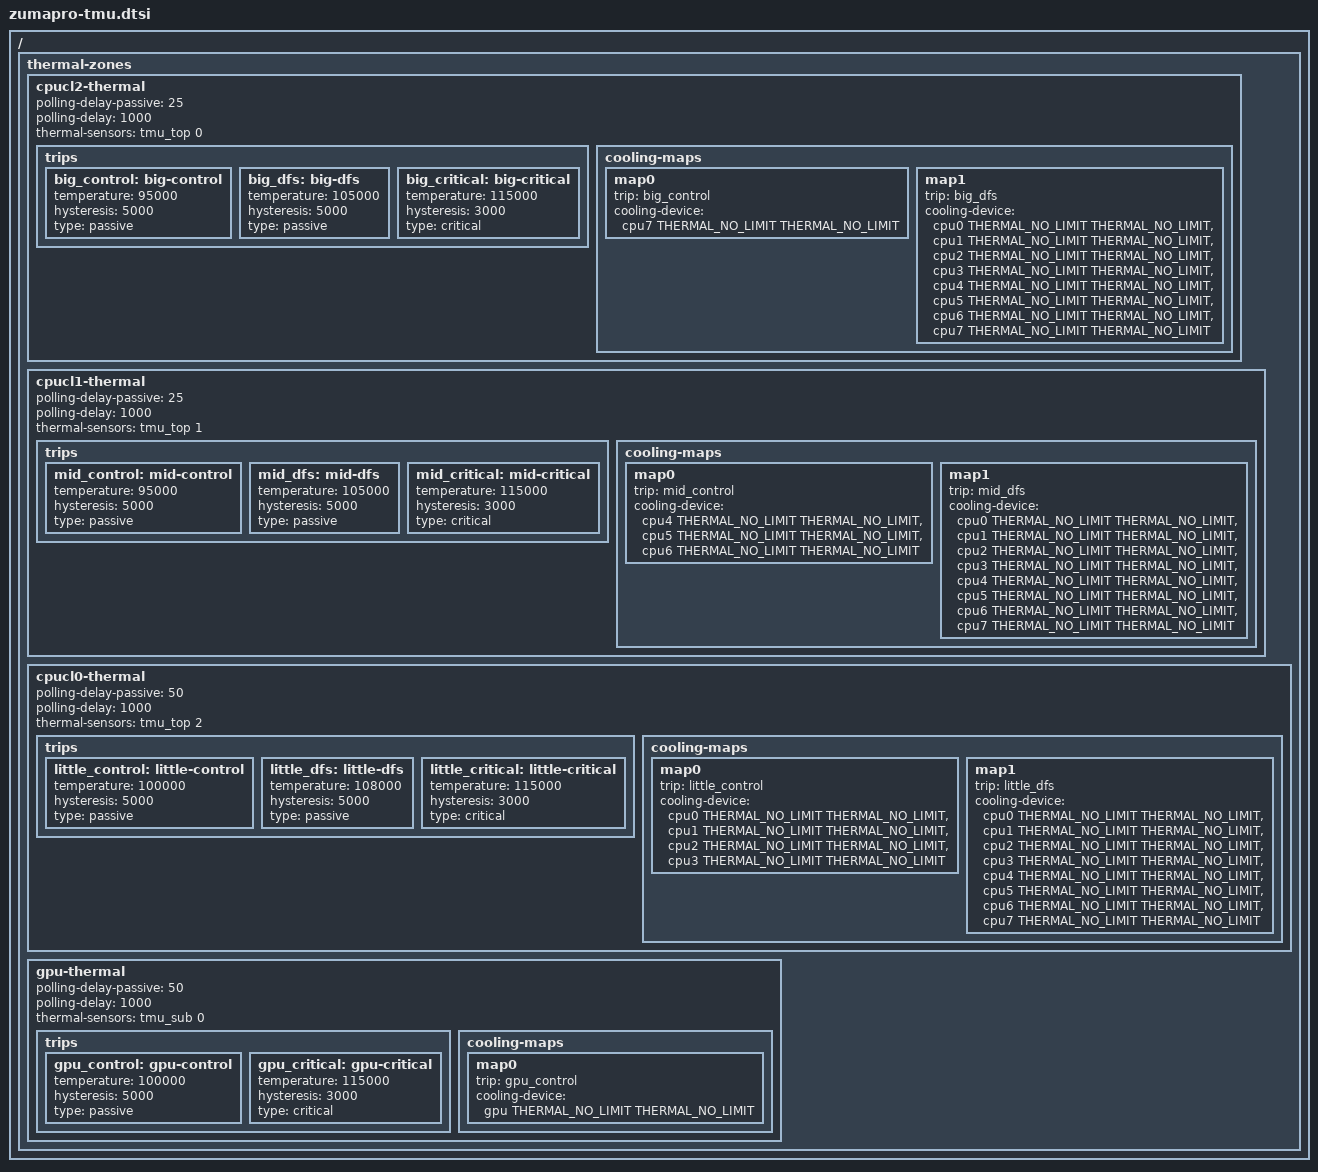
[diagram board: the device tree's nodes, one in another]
// SPDX-License-Identifier: GPL-2.0

#include <dt-bindings/thermal/thermal.h>

/ {
	thermal-zones {
		cpucl2-thermal {
			polling-delay-passive = <25>;
			polling-delay = <1000>;
			thermal-sensors = <&tmu_top 0>;

			trips {
				big_control: big-control {
					temperature = <95000>;
					hysteresis = <5000>;
					type = "passive";
				};

				big_dfs: big-dfs {
					temperature = <105000>;
					hysteresis = <5000>;
					type = "passive";
				};

				big_critical: big-critical {
					temperature = <115000>;
					hysteresis = <3000>;
					type = "critical";
				};
			};

			cooling-maps {
				map0 {
					trip = <&big_control>;
					cooling-device = <&cpu7 THERMAL_NO_LIMIT THERMAL_NO_LIMIT>;
				};

				map1 {
					trip = <&big_dfs>;
					cooling-device = <&cpu0 THERMAL_NO_LIMIT THERMAL_NO_LIMIT>,
							 <&cpu1 THERMAL_NO_LIMIT THERMAL_NO_LIMIT>,
							 <&cpu2 THERMAL_NO_LIMIT THERMAL_NO_LIMIT>,
							 <&cpu3 THERMAL_NO_LIMIT THERMAL_NO_LIMIT>,
							 <&cpu4 THERMAL_NO_LIMIT THERMAL_NO_LIMIT>,
							 <&cpu5 THERMAL_NO_LIMIT THERMAL_NO_LIMIT>,
							 <&cpu6 THERMAL_NO_LIMIT THERMAL_NO_LIMIT>,
							 <&cpu7 THERMAL_NO_LIMIT THERMAL_NO_LIMIT>;
				};
			};
		};

		cpucl1-thermal {
			polling-delay-passive = <25>;
			polling-delay = <1000>;
			thermal-sensors = <&tmu_top 1>;

			trips {
				mid_control: mid-control {
					temperature = <95000>;
					hysteresis = <5000>;
					type = "passive";
				};

				mid_dfs: mid-dfs {
					temperature = <105000>;
					hysteresis = <5000>;
					type = "passive";
				};

				mid_critical: mid-critical {
					temperature = <115000>;
					hysteresis = <3000>;
					type = "critical";
				};
			};

			cooling-maps {
				map0 {
					trip = <&mid_control>;
					cooling-device = <&cpu4 THERMAL_NO_LIMIT THERMAL_NO_LIMIT>,
							 <&cpu5 THERMAL_NO_LIMIT THERMAL_NO_LIMIT>,
							 <&cpu6 THERMAL_NO_LIMIT THERMAL_NO_LIMIT>;
				};

				map1 {
					trip = <&mid_dfs>;
					cooling-device = <&cpu0 THERMAL_NO_LIMIT THERMAL_NO_LIMIT>,
							 <&cpu1 THERMAL_NO_LIMIT THERMAL_NO_LIMIT>,
							 <&cpu2 THERMAL_NO_LIMIT THERMAL_NO_LIMIT>,
							 <&cpu3 THERMAL_NO_LIMIT THERMAL_NO_LIMIT>,
							 <&cpu4 THERMAL_NO_LIMIT THERMAL_NO_LIMIT>,
							 <&cpu5 THERMAL_NO_LIMIT THERMAL_NO_LIMIT>,
							 <&cpu6 THERMAL_NO_LIMIT THERMAL_NO_LIMIT>,
							 <&cpu7 THERMAL_NO_LIMIT THERMAL_NO_LIMIT>;
				};
			};
		};

		cpucl0-thermal {
			polling-delay-passive = <50>;
			polling-delay = <1000>;
			thermal-sensors = <&tmu_top 2>;

			trips {
				little_control: little-control {
					temperature = <100000>;
					hysteresis = <5000>;
					type = "passive";
				};

				little_dfs: little-dfs {
					temperature = <108000>;
					hysteresis = <5000>;
					type = "passive";
				};

				little_critical: little-critical {
					temperature = <115000>;
					hysteresis = <3000>;
					type = "critical";
				};
			};

			cooling-maps {
				map0 {
					trip = <&little_control>;
					cooling-device = <&cpu0 THERMAL_NO_LIMIT THERMAL_NO_LIMIT>,
							 <&cpu1 THERMAL_NO_LIMIT THERMAL_NO_LIMIT>,
							 <&cpu2 THERMAL_NO_LIMIT THERMAL_NO_LIMIT>,
							 <&cpu3 THERMAL_NO_LIMIT THERMAL_NO_LIMIT>;
				};

				map1 {
					trip = <&little_dfs>;
					cooling-device = <&cpu0 THERMAL_NO_LIMIT THERMAL_NO_LIMIT>,
							 <&cpu1 THERMAL_NO_LIMIT THERMAL_NO_LIMIT>,
							 <&cpu2 THERMAL_NO_LIMIT THERMAL_NO_LIMIT>,
							 <&cpu3 THERMAL_NO_LIMIT THERMAL_NO_LIMIT>,
							 <&cpu4 THERMAL_NO_LIMIT THERMAL_NO_LIMIT>,
							 <&cpu5 THERMAL_NO_LIMIT THERMAL_NO_LIMIT>,
							 <&cpu6 THERMAL_NO_LIMIT THERMAL_NO_LIMIT>,
							 <&cpu7 THERMAL_NO_LIMIT THERMAL_NO_LIMIT>;
				};
			};
		};

		gpu-thermal {
			polling-delay-passive = <50>;
			polling-delay = <1000>;
			thermal-sensors = <&tmu_sub 0>;

			trips {
				gpu_control: gpu-control {
					temperature = <100000>;
					hysteresis = <5000>;
					type = "passive";
				};

				gpu_critical: gpu-critical {
					temperature = <115000>;
					hysteresis = <3000>;
					type = "critical";
				};
			};

			cooling-maps {
				map0 {
					trip = <&gpu_control>;
					cooling-device = <&gpu THERMAL_NO_LIMIT THERMAL_NO_LIMIT>;
				};
			};
		};
	};
};
